VERSION "0.1"

NS_ :

BS_ :

BU_ : bms_lv dash dspace sens_front sens_rear tlb_bat

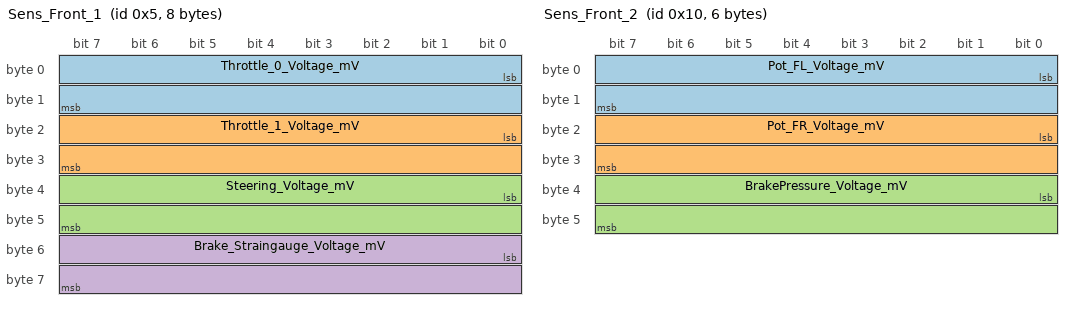
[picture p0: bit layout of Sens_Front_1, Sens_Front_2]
BO_ 5 Sens_Front_1: 8 sens_front
	SG_ Throttle_0_Voltage_mV : 0|16@1+ (1,0) [0|65535] "" dspace
	SG_ Throttle_1_Voltage_mV : 16|16@1+ (1,0) [0|65535] "" dspace
	SG_ Steering_Voltage_mV : 32|16@1+ (1,0) [0|65535] "" dspace
	SG_ Brake_Straingauge_Voltage_mV : 48|16@1+ (1,0) [0|65535] "" dspace

BO_ 16 Sens_Front_2: 6 sens_front
	SG_ Pot_FL_Voltage_mV : 0|16@1+ (1,0) [0|65535] "" dspace
	SG_ Pot_FR_Voltage_mV : 16|16@1+ (1,0) [0|65535] "" dspace
	SG_ BrakePressure_Voltage_mV : 32|16@1+ (1,0) [0|65535] "" dspace

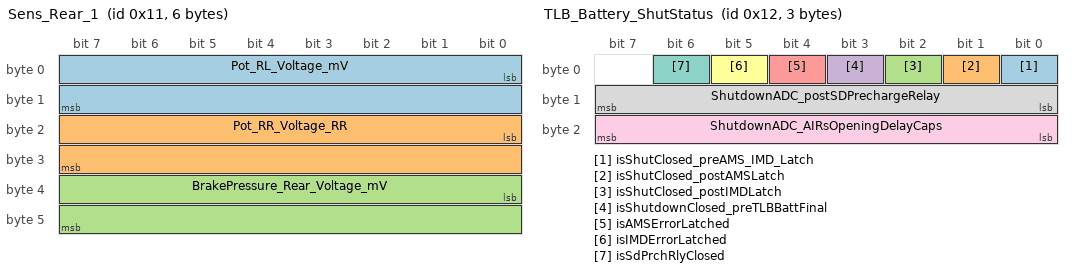
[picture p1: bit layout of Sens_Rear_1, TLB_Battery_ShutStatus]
BO_ 17 Sens_Rear_1: 6 sens_rear
	SG_ Pot_RL_Voltage_mV : 0|16@1+ (1,0) [0|65535] "" dspace
	SG_ Pot_RR_Voltage_RR : 16|16@1+ (1,0) [0|65535] "" dspace
	SG_ BrakePressure_Rear_Voltage_mV : 32|16@1+ (1,0) [0|65535] "" dspace

BO_ 18 TLB_Battery_ShutStatus: 3 tlb_bat
	SG_ isShutClosed_preAMS_IMD_Latch : 0|1@1+ (1,0) [0|1] "" dspace
	SG_ isShutClosed_postAMSLatch : 1|1@1+ (1,0) [0|1] "" dspace
	SG_ isShutClosed_postIMDLatch : 2|1@1+ (1,0) [0|1] "" dspace
	SG_ isShutdownClosed_preTLBBattFinal : 3|1@1+ (1,0) [0|1] "" dspace
	SG_ isAMSErrorLatched : 4|1@1+ (1,0) [0|1] "" dspace
	SG_ isIMDErrorLatched : 5|1@1+ (1,0) [0|1] "" dspace
	SG_ isSdPrchRlyClosed : 6|1@1+ (1,0) [0|1] "" dspace
	SG_ ShutdownADC_postSDPrechargeRelay : 8|8@1+ (0.117,0) [0|255] "V" dspace
	SG_ ShutdownADC_AIRsOpeningDelayCaps : 16|8@1+ (0.117,0) [0|255] "V" dspace

BO_ 19 TLB_Battery_TSALStatus: 3 tlb_bat
	SG_ TSAL_isGreenON : 0|1@1+ (1,0) [0|1] "" dspace
	SG_ TSAL_isAIRPosClosed : 1|1@1+ (1,0) [0|1] "" dspace
	SG_ TSAL_IsAIRNegClosed : 2|1@1+ (1,0) [0|1] "" dspace
	SG_ TSAL_IsRelayPrechargeClosed : 3|1@1+ (1,0) [0|1] "" dspace
	SG_ TSAL_isDCBusOver60V : 4|1@1+ (1,0) [0|1] "" dspace
	SG_ IntentionalState_AIRPos : 5|1@1+ (1,0) [0|1] "" dspace
	SG_ IntentionalState_AIRNeg : 6|1@1+ (1,0) [0|1] "" dspace
	SG_ IntentionalState_RelayPrecharge : 7|1@1+ (1,0) [0|1] "" dspace
	SG_ SCS_Short2GND_AirPos : 8|1@1+ (1,0) [0|1] "" dspace
	SG_ SCS_Short2GND_AirNeg : 9|1@1+ (1,0) [0|1] "" dspace
	SG_ SCS_isAnyShort2GND_Present : 10|1@1+ (1,0) [0|1] "" dspace
	SG_ Imp_isAnyImp_Present : 11|1@1+ (1,0) [0|1] "" dspace
	SG_ Imp_isAIRPosImp_Present : 12|1@1+ (1,0) [0|1] "" dspace
	SG_ Imp_isAIRNegImp_Present : 13|1@1+ (1,0) [0|1] "" dspace
	SG_ Imp_isRelayPrechargeImp_Present : 14|1@1+ (1,0) [0|1] "" dspace
	SG_ Imp_isDCBusVoltageImp_Present : 15|1@1+ (1,0) [0|1] "" dspace
	SG_ Imp_isAnyImp_Latched : 16|1@1+ (1,0) [0|1] "" dspace

BO_ 1026 Sens_Rear_2: 4 sens_rear
	SG_ CoolingPressure_DX_Voltage_mV : 0|16@1+ (1,0) [0|65535] "" dspace
	SG_ CoolingPressure_SX_Voltage_mV : 16|16@1+ (1,0) [0|65535] "" dspace

CM_ BU_ bms_lv "battery-management-system low-voltage";
CM_ BU_ dash "dashboard ECU";
CM_ BU_ dspace "automotive ECU";
CM_ BU_ sens_front "sensorboard front ECU";
CM_ BU_ sens_rear "sensorboard rear ECU";
CM_ BU_ tlb_bat "tsal-latch-board battery ECU";
CM_ BO_ 260 "(period: 2000 ms)";
CM_ BO_ 256 "(period: 100 ms)";
CM_ BO_ 22 "(period: 10 ms)";
CM_ BO_ 1026 "(period: 10 ms)";
CM_ BO_ 1025 "(period: 10 ms)";
CM_ BO_ 261 "(period: 2000 ms)";
CM_ BO_ 5 "(period: 10 ms)";
CM_ BO_ 258 "(period: 100 ms)";
CM_ BO_ 16 "(period: 10 ms)";
CM_ BO_ 18 "(period: 100 ms)";
CM_ BO_ 19 "(period: 100 ms)";
CM_ BO_ 288 "(period: 10 ms)";
CM_ BO_ 17 "(period: 10 ms)";
CM_ BO_ 49 "(period: 10 ms)";
CM_ BO_ 48 "(period: 10 ms)";
CM_ BO_ 259 "(period: 100 ms)";
CM_ BO_ 289 "(period: 10 ms)";
CM_ BO_ 257 "(period: 100 ms)";
CM_ BO_ 1024 "(period: 10 ms)";
CM_ BO_ 38 "(period: 500 ms)";

BA_DEF_ BO_ "GenMsgSendType" ENUM "NoMsgSendType","Cyclic","IfActive","cyclicIfActive","NotUsed";
BA_DEF_ SG_ "GenSigSendType" ENUM "NoSigSendType","Cyclic","OnWrite","OnWriteWithRepetition","OnChange","OnChangeWithRepetition","IfActive","IfActiveWithRepetition","NotUsed";
BA_DEF_DEF_ "GenMsgSendType" "NoMsgSendType";
BA_DEF_DEF_ "GenSigSendType" "NoSigSendType";
